VERSION ""

NS_ :

BS_:

BU_:

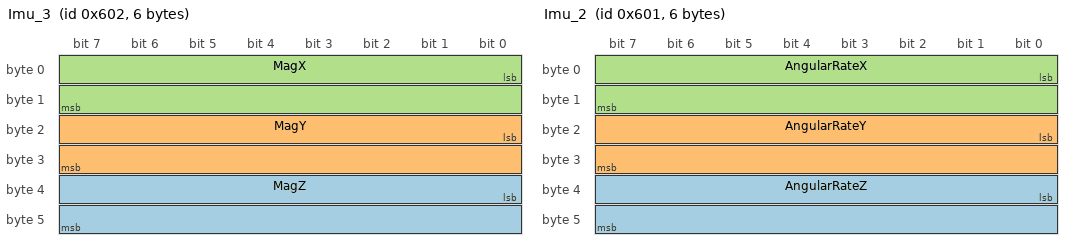
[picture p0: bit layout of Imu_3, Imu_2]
BO_ 1538 Imu_3: 6 Vector__XXX
 SG_ MagZ : 32|16@1- (0.2,0) [-6553.6|6553.4] "uT" Vector__XXX
 SG_ MagY : 16|16@1- (0.2,0) [-6553.6|6553.4] "uT" Vector__XXX
 SG_ MagX : 0|16@1- (0.2,0) [-6553.6|6553.4] "uT" Vector__XXX

BO_ 1537 Imu_2: 6 Vector__XXX
 SG_ AngularRateZ : 32|16@1- (0.01,0) [-327.68|327.67] "deg/s" Vector__XXX
 SG_ AngularRateY : 16|16@1- (0.01,0) [-327.68|327.67] "deg/s" Vector__XXX
 SG_ AngularRateX : 0|16@1- (0.01,0) [-327.68|327.67] "deg/s" Vector__XXX

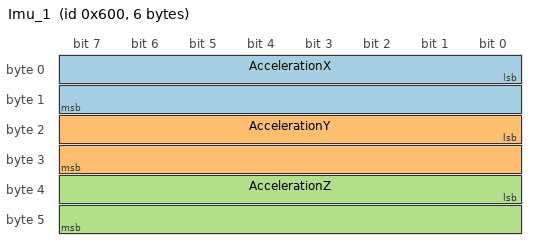
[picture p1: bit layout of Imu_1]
BO_ 1536 Imu_1: 6 Vector__XXX
 SG_ AccelerationX : 0|16@1- (0.00025,0) [-8.192|8.19175] "m/s^2" Vector__XXX
 SG_ AccelerationY : 16|16@1- (0.00025,0) [-8.192|8.19175] "m/s^2" Vector__XXX
 SG_ AccelerationZ : 32|16@1- (0.00025,0) [-8.192|8.19175] "m/s^2" Vector__XXX

CM_ BO_ 1538 "GNSS IMU";
CM_ SG_ 1538 MagZ "X magnetometer reading";
CM_ SG_ 1538 MagY "X magnetometer reading";
CM_ SG_ 1538 MagX "X magnetometer reading";
CM_ BO_ 1537 "GNSS IMU";
CM_ SG_ 1537 AngularRateZ "Z angular rate";
CM_ SG_ 1537 AngularRateY "Y angular rate";
CM_ SG_ 1537 AngularRateX "X angular rate";
CM_ BO_ 1536 "GNSS IMU";
CM_ SG_ 1536 AccelerationX "X acceleration";
CM_ SG_ 1536 AccelerationY "Y acceleration";
CM_ SG_ 1536 AccelerationZ "Z acceleration";
BA_DEF_  "BusType" STRING ;
BA_DEF_  "ProtocolType" STRING ;
BA_DEF_DEF_  "BusType" "";
BA_DEF_DEF_  "ProtocolType" "";
BA_ "BusType" "CAN";
